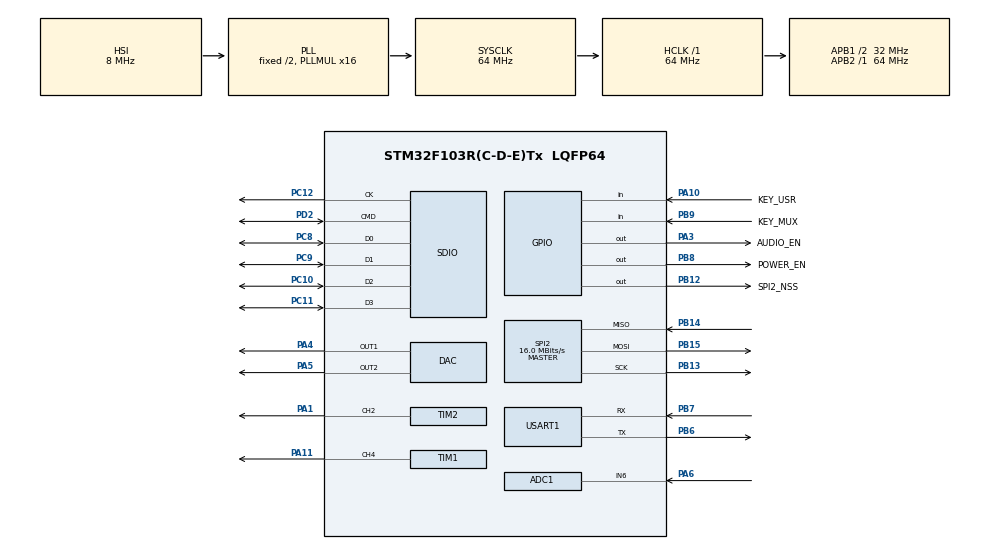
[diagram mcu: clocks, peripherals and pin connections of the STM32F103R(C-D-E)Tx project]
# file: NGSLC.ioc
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ADC1.Channel-34\#ChannelRegularConversion=ADC_CHANNEL_6
ADC1.NbrOfConversionFlag=1
ADC1.Rank-34\#ChannelRegularConversion=1
ADC1.SamplingTime-34\#ChannelRegularConversion=ADC_SAMPLETIME_1CYCLE_5
ADC1.master=1
DAC.DAC_Trigger=DAC_TRIGGER_T7_TRGO
DAC.DAC_Trigger2=DAC_TRIGGER_T7_TRGO
Dma.DAC_CH1.0.Direction=DMA_MEMORY_TO_PERIPH
Dma.DAC_CH1.0.Instance=DMA2_Channel3
Dma.DAC_CH1.0.MemDataAlignment=DMA_MDATAALIGN_HALFWORD
Dma.DAC_CH1.0.MemInc=DMA_MINC_ENABLE
Dma.DAC_CH1.0.Mode=DMA_NORMAL
Dma.DAC_CH1.0.PeriphDataAlignment=DMA_PDATAALIGN_HALFWORD
Dma.DAC_CH1.0.PeriphInc=DMA_PINC_DISABLE
Dma.DAC_CH1.0.Priority=DMA_PRIORITY_LOW
Dma.DAC_CH2.1.Direction=DMA_MEMORY_TO_PERIPH
Dma.DAC_CH2.1.Instance=DMA2_Channel4
Dma.DAC_CH2.1.MemDataAlignment=DMA_MDATAALIGN_HALFWORD
Dma.DAC_CH2.1.MemInc=DMA_MINC_ENABLE
Dma.DAC_CH2.1.Mode=DMA_NORMAL
Dma.DAC_CH2.1.PeriphDataAlignment=DMA_PDATAALIGN_HALFWORD
Dma.DAC_CH2.1.PeriphInc=DMA_PINC_DISABLE
Dma.DAC_CH2.1.Priority=DMA_PRIORITY_LOW
Dma.Request0=DAC_CH1
Dma.Request1=DAC_CH2
FREERTOS.BinarySemaphores01=DAC_Complete_Flag,Dynamic,NULL
FREERTOS.INCLUDE_uxTaskGetStackHighWaterMark=1
FREERTOS.Queues01=DAC_CMD,16,uint32_t,NULL,Dynamic,NULL,NULL;LED_CMD,16,uint32_t,NULL,Dynamic,NULL,NULL;DAC_Buffer,3,uint32_t,NULL,Dynamic,NULL,NULL
FREERTOS.Tasks01=defaultTask,2,1024,StartDefaultTask,As weak,NULL,Dynamic,NULL,NULL;DACTask,0,128,DACOutput,As weak,NULL,Dynamic,NULL,NULL;LEDTask,3,128,LEDOpra,As weak,NULL,Dynamic,NULL,NULL;WavTask,1,1024,Wav_Task,As weak,NULL,Dynamic,NULL,NULL;SimpleLED,-2,128,SimpleLED_Handle,As weak,NULL,Dynamic,NULL,NULL
FREERTOS.configTOTAL_HEAP_SIZE=46000
Mcu.Family=STM32F1
Mcu.Name=STM32F103R(C-D-E)Tx
Mcu.Package=LQFP64
NVIC.DMA2_Channel3_IRQn=true\:5\:0\:false\:false\:true\:true
NVIC.DMA2_Channel4_5_IRQn=true\:5\:0\:false\:false\:true\:true
NVIC.PriorityGroup=NVIC_PRIORITYGROUP_4
NVIC.TIM8_UP_IRQn=true\:0\:0\:false\:false\:true\:false
NVIC.TimeBase=TIM8_UP_IRQn
NVIC.TimeBaseIP=TIM8
PA1.Signal=S_TIM2_CH2
PA10.GPIO_Label=KEY_USR
PA10.GPIO_PuPd=GPIO_PULLUP
PA10.Signal=GPIO_Input
PA11.Signal=S_TIM1_CH4
PA13.Mode=Serial_Wire
PA13.Signal=SYS_JTMS-SWDIO
PA14.Mode=Serial_Wire
PA14.Signal=SYS_JTCK-SWCLK
PA3.GPIO_Label=AUDIO_EN
PA3.Signal=GPIO_Output
PA4.Signal=COMP_DAC1_group
PA5.Signal=COMP_DAC2_group
PA6.Signal=ADCx_IN6
PB12.GPIO_Label=SPI2_NSS
PB12.Signal=GPIO_Output
PB13.Mode=Full_Duplex_Master
PB13.Signal=SPI2_SCK
PB14.Mode=Full_Duplex_Master
PB14.Signal=SPI2_MISO
PB15.Mode=Full_Duplex_Master
PB15.Signal=SPI2_MOSI
PB6.Mode=Asynchronous
PB6.Signal=USART1_TX
PB7.Mode=Asynchronous
PB7.Signal=USART1_RX
PB8.GPIO_Label=POWER_EN
PB8.Signal=GPIO_Output
PB9.GPIO_Label=KEY_MUX
PB9.GPIO_PuPd=GPIO_PULLDOWN
PB9.Signal=GPIO_Input
PC10.Mode=SD_4_bits_Wide_bus
PC10.Signal=SDIO_D2
PC11.Mode=SD_4_bits_Wide_bus
PC11.Signal=SDIO_D3
PC12.Mode=SD_4_bits_Wide_bus
PC12.Signal=SDIO_CK
PC8.Mode=SD_4_bits_Wide_bus
PC8.Signal=SDIO_D0
PC9.Mode=SD_4_bits_Wide_bus
PC9.Signal=SDIO_D1
PD2.Mode=SD_4_bits_Wide_bus
PD2.Signal=SDIO_CMD
ProjectManager.HeapSize=0x200
ProjectManager.StackSize=0x400
ProjectManager.TargetToolchain=Makefile
RCC.ADCPresc=RCC_ADCPCLK2_DIV6
RCC.AHBFreq_Value=64000000
RCC.APB1CLKDivider=RCC_HCLK_DIV2
RCC.APB1Freq_Value=32000000
RCC.APB1TimFreq_Value=64000000
RCC.APB2Freq_Value=64000000
RCC.APB2TimFreq_Value=64000000
RCC.HCLKFreq_Value=64000000
RCC.PLLMUL=RCC_PLL_MUL16
RCC.SYSCLKFreq_VALUE=64000000
RCC.SYSCLKSource=RCC_SYSCLKSOURCE_PLLCLK
RCC.USBFreq_Value=64000000
SDIO.ClockDiv=40
SH.ADCx_IN6.0=ADC1_IN6,IN6
SH.COMP_DAC1_group.0=DAC_OUT1,DAC_OUT1
SH.COMP_DAC2_group.0=DAC_OUT2,DAC_OUT2
SH.S_TIM1_CH4.0=TIM1_CH4,PWM Generation4 CH4
SH.S_TIM2_CH2.0=TIM2_CH2,PWM Generation2 CH2
SPI2.CalculateBaudRate=16.0 MBits/s
SPI2.Direction=SPI_DIRECTION_2LINES
SPI2.Mode=SPI_MODE_MASTER
SPI2.VirtualType=VM_MASTER
TIM1.Channel-PWM\ Generation4\ CH4=TIM_CHANNEL_4
TIM2.Channel-PWM\ Generation2\ CH2=TIM_CHANNEL_2
TIM7.Period=2908
TIM7.TIM_MasterOutputTrigger=TIM_TRGO_UPDATE
USART1.VirtualMode=VM_ASYNC
VP_FATFS_VS_SDIO.Mode=SDIO
VP_FREERTOS_VS_ENABLE.Mode=Enabled
VP_SYS_VS_tim8.Mode=TIM8
VP_TIM7_VS_ClockSourceINT.Mode=Enable_Timer
board=NGSLC

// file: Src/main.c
/**
  ******************************************************************************
  * File Name          : main.c
  * Description        : Main program body
  ******************************************************************************
  * This notice applies to any and all portions of this file
  * that are not between comment pairs USER CODE BEGIN and
  * USER CODE END. Other portions of this file, whether
  * inserted by the user or by software development tools
  * are owned by their respective copyright owners.
  *
  * Copyright (c) 2017 STMicroelectronics International N.V.
  * All rights reserved.
  *
  * Redistribution and use in source and binary forms, with or without
  * modification, are permitted, provided that the following conditions are met:
  *
  * 1. Redistribution of source code must retain the above copyright notice,
  *    this list of conditions and the following disclaimer.
  * 2. Redistributions in binary form must reproduce the above copyright notice,
  *    this list of conditions and the following disclaimer in the documentation
  *    and/or other materials provided with the distribution.
  * 3. Neither the name of STMicroelectronics nor the names of other
  *    contributors to this software may be used to endorse or promote products
  *    derived from this software without specific written permission.
  * 4. This software, including modifications and/or derivative works of this
  *    software, must execute solely and exclusively on microcontroller or
  *    microprocessor devices manufactured by or for STMicroelectronics.
  * 5. Redistribution and use of this software other than as permitted under
  *    this license is void and will automatically terminate your rights under
  *    this license.
  *
  * THIS SOFTWARE IS PROVIDED BY STMICROELECTRONICS AND CONTRIBUTORS "AS IS"
  * AND ANY EXPRESS, IMPLIED OR STATUTORY WARRANTIES, INCLUDING, BUT NOT
  * LIMITED TO, THE IMPLIED WARRANTIES OF MERCHANTABILITY, FITNESS FOR A
  * PARTICULAR PURPOSE AND NON-INFRINGEMENT OF THIRD PARTY INTELLECTUAL PROPERTY
  * RIGHTS ARE DISCLAIMED TO THE FULLEST EXTENT PERMITTED BY LAW. IN NO EVENT
  * SHALL STMICROELECTRONICS OR CONTRIBUTORS BE LIABLE FOR ANY DIRECT, INDIRECT,
  * INCIDENTAL, SPECIAL, EXEMPLARY, OR CONSEQUENTIAL DAMAGES (INCLUDING, BUT NOT
  * LIMITED TO, PROCUREMENT OF SUBSTITUTE GOODS OR SERVICES; LOSS OF USE, DATA,
  * OR PROFITS; OR BUSINESS INTERRUPTION) HOWEVER CAUSED AND ON ANY THEORY OF
  * LIABILITY, WHETHER IN CONTRACT, STRICT LIABILITY, OR TORT (INCLUDING
  * NEGLIGENCE OR OTHERWISE) ARISING IN ANY WAY OUT OF THE USE OF THIS SOFTWARE,
  * EVEN IF ADVISED OF THE POSSIBILITY OF SUCH DAMAGE.
  *
  ******************************************************************************
  */
#include "main.h"
#include "stm32f1xx_hal.h"
#include "cmsis_os.h"
#include "adc.h"
#include "dac.h"
#include "dma.h"
#include "fatfs.h"
#include "sdio.h"
#include "spi.h"
#include "tim.h"
#include "usart.h"
#include "gpio.h"

/* USER CODE BEGIN Includes */
#include "mx-audio.h"
#include "mx-gpio.h"
#include "DEBUG.h"
/* USER CODE END Includes */

/* USER CODE BEGIN PV */
/* Private variables ---------------------------------------------------------*/

/* USER CODE END PV */

void SystemClock_Config(void);
void MX_FREERTOS_Init(void);

/* USER CODE BEGIN PFP */
/* Private function prototypes -----------------------------------------------*/

/* USER CODE END PFP */

/* USER CODE BEGIN 0 */

char EBmonitorBuffer[EBmonitorBufLen];
/* USER CODE END 0 */

int main(void)
{

  /* MCU Configuration----------------------------------------------------------*/

  /* Reset of all peripherals, Initializes the Flash interface and the Systick. */
  HAL_Init();

  /* Configure the system clock */
  SystemClock_Config();

  /* Initialize all configured peripherals */
  MX_GPIO_Init();
  MX_DMA_Init();
  MX_USART1_UART_Init();
  MX_SDIO_SD_Init();
  MX_DAC_Init();
  MX_SPI2_Init();
  MX_TIM1_Init();
  MX_TIM2_Init();
  MX_ADC1_Init();
  MX_TIM7_Init();

  /* USER CODE BEGIN 2 */
  AFIO_RELEASE();
  MX_Audio_Init();

  EBmonitor_Init();
  /* USER CODE END 2 */

  /* Call init function for freertos objects (in freertos.c) */
  MX_FREERTOS_Init();

  /* Start scheduler */
  osKernelStart();

  /* We should never get here as control is now taken by the scheduler */

  /* Infinite loop */
  while (1)
  {

  }

}

/** System Clock Configuration
*/
void SystemClock_Config(void)
{

  RCC_OscInitTypeDef RCC_OscInitStruct;
  RCC_ClkInitTypeDef RCC_ClkInitStruct;
  RCC_PeriphCLKInitTypeDef PeriphClkInit;

    /**Initializes the CPU, AHB and APB busses clocks
    */
  RCC_OscInitStruct.OscillatorType = RCC_OSCILLATORTYPE_HSI;
  RCC_OscInitStruct.HSIState = RCC_HSI_ON;
  RCC_OscInitStruct.HSICalibrationValue = 16;
  RCC_OscInitStruct.PLL.PLLState = RCC_PLL_ON;
  RCC_OscInitStruct.PLL.PLLSource = RCC_PLLSOURCE_HSI_DIV2;
  RCC_OscInitStruct.PLL.PLLMUL = RCC_PLL_MUL16;
  if (HAL_RCC_OscConfig(&RCC_OscInitStruct) != HAL_OK)
  {
    _Error_Handler(__FILE__, __LINE__);
  }

    /**Initializes the CPU, AHB and APB busses clocks
    */
  RCC_ClkInitStruct.ClockType = RCC_CLOCKTYPE_HCLK|RCC_CLOCKTYPE_SYSCLK
                              |RCC_CLOCKTYPE_PCLK1|RCC_CLOCKTYPE_PCLK2;
  RCC_ClkInitStruct.SYSCLKSource = RCC_SYSCLKSOURCE_PLLCLK;
  RCC_ClkInitStruct.AHBCLKDivider = RCC_SYSCLK_DIV1;
  RCC_ClkInitStruct.APB1CLKDivider = RCC_HCLK_DIV2;
  RCC_ClkInitStruct.APB2CLKDivider = RCC_HCLK_DIV1;

  if (HAL_RCC_ClockConfig(&RCC_ClkInitStruct, FLASH_LATENCY_2) != HAL_OK)
  {
    _Error_Handler(__FILE__, __LINE__);
  }

  PeriphClkInit.PeriphClockSelection = RCC_PERIPHCLK_ADC;
  PeriphClkInit.AdcClockSelection = RCC_ADCPCLK2_DIV6;
  if (HAL_RCCEx_PeriphCLKConfig(&PeriphClkInit) != HAL_OK)
  {
    _Error_Handler(__FILE__, __LINE__);
  }

    /**Configure the Systick interrupt time
    */
  HAL_SYSTICK_Config(HAL_RCC_GetHCLKFreq()/1000);

    /**Configure the Systick
    */
  HAL_SYSTICK_CLKSourceConfig(SYSTICK_CLKSOURCE_HCLK);

  /* SysTick_IRQn interrupt configuration */
  HAL_NVIC_SetPriority(SysTick_IRQn, 15, 0);
}

void HAL_TIM_PeriodElapsedCallback(TIM_HandleTypeDef *htim)
{
  if (htim->Instance == TIM8) {
    HAL_IncTick();
  }
}

void _Error_Handler(char * file, int line)
{
  while(1)
  {
  }
}

/************************ (C) COPYRIGHT STMicroelectronics *****END OF FILE****/
